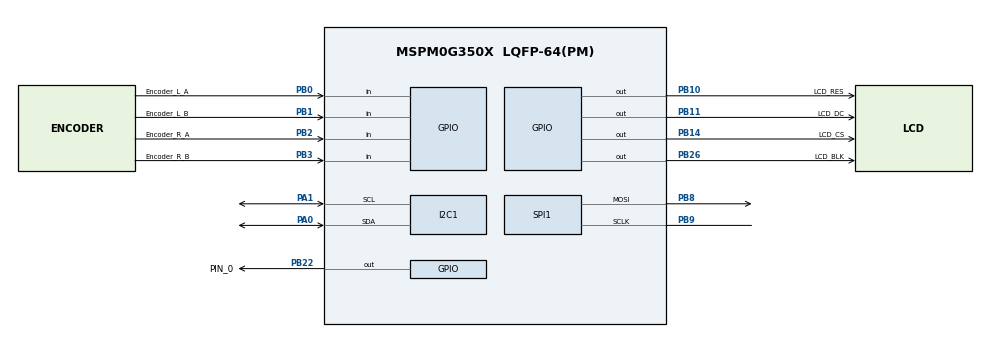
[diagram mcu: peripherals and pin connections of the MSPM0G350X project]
/**
 * @cliArgs --device "MSPM0G350X" --part "Default" --package "LQFP-64(PM)" --product "mspm0_sdk@2.10.00.04"
 * @versions {"tool":"1.26.2+4477"}
 */

/**
 * Import the modules used in this configuration.
 */
const GPIO          = scripting.addModule("/ti/driverlib/GPIO", {}, false);
const GPIO1         = GPIO.addInstance();
const GPIO2         = GPIO.addInstance();
const GPIO3         = GPIO.addInstance();
const I2C           = scripting.addModule("/ti/driverlib/I2C", {}, false);
const I2C1          = I2C.addInstance();
const PWM           = scripting.addModule("/ti/driverlib/PWM", {}, false);
const PWM1          = PWM.addInstance();
const PWM2          = PWM.addInstance();
const SPI           = scripting.addModule("/ti/driverlib/SPI", {}, false);
const SPI1          = SPI.addInstance();
const SYSCTL        = scripting.addModule("/ti/driverlib/SYSCTL");
const SYSTICK       = scripting.addModule("/ti/driverlib/SYSTICK");
const TIMER         = scripting.addModule("/ti/driverlib/TIMER", {}, false);
const TIMER1        = TIMER.addInstance();
const UART          = scripting.addModule("/ti/driverlib/UART", {}, false);
const UART1         = UART.addInstance();
const ProjectConfig = scripting.addModule("/ti/project_config/ProjectConfig");

/**
 * Write custom configuration values to the imported modules.
 */
const divider9       = system.clockTree["UDIV"];
divider9.divideValue = 2;

const mux4       = system.clockTree["EXHFMUX"];
mux4.inputSelect = "EXHFMUX_XTAL";

const mux8       = system.clockTree["HSCLKMUX"];
mux8.inputSelect = "HSCLKMUX_SYSPLL2X";

const mux12       = system.clockTree["SYSPLLMUX"];
mux12.inputSelect = "zSYSPLLMUX_HFCLK";

const pinFunction4       = system.clockTree["HFXT"];
pinFunction4.inputFreq   = 40;
pinFunction4.HFXTStartup = 10;
pinFunction4.enable      = true;

GPIO1.$name                              = "User_led";
GPIO1.associatedPins[0].$name            = "PIN_0";
GPIO1.associatedPins[0].internalResistor = "PULL_DOWN";
GPIO1.associatedPins[0].pin.$assign      = "PB22";

const Board = scripting.addModule("/ti/driverlib/Board", {}, false);

GPIO2.$name                         = "Encoder_Input_Pin";
GPIO2.associatedPins.create(4);
GPIO2.associatedPins[0].$name       = "Encoder_L_A";
GPIO2.associatedPins[0].direction   = "INPUT";
GPIO2.associatedPins[0].interruptEn = true;
GPIO2.associatedPins[0].polarity    = "RISE_FALL";
GPIO2.associatedPins[0].pin.$assign = "PB0";
GPIO2.associatedPins[1].$name       = "Encoder_L_B";
GPIO2.associatedPins[1].direction   = "INPUT";
GPIO2.associatedPins[1].interruptEn = true;
GPIO2.associatedPins[1].polarity    = "RISE_FALL";
GPIO2.associatedPins[1].pin.$assign = "PB1";
GPIO2.associatedPins[2].$name       = "Encoder_R_A";
GPIO2.associatedPins[2].direction   = "INPUT";
GPIO2.associatedPins[2].interruptEn = true;
GPIO2.associatedPins[2].polarity    = "RISE_FALL";
GPIO2.associatedPins[2].pin.$assign = "PB2";
GPIO2.associatedPins[3].$name       = "Encoder_R_B";
GPIO2.associatedPins[3].direction   = "INPUT";
GPIO2.associatedPins[3].interruptEn = true;
GPIO2.associatedPins[3].polarity    = "RISE_FALL";
GPIO2.associatedPins[3].pin.$assign = "PB3";

GPIO3.$name                          = "LCD_CTRL";
GPIO3.associatedPins.create(4);
GPIO3.associatedPins[0].$name        = "LCD_RES";
GPIO3.associatedPins[0].initialValue = "SET";
GPIO3.associatedPins[0].pin.$assign  = "PB10";
GPIO3.associatedPins[1].$name        = "LCD_DC";
GPIO3.associatedPins[1].initialValue = "SET";
GPIO3.associatedPins[1].pin.$assign  = "PB11";
GPIO3.associatedPins[2].$name        = "LCD_CS";
GPIO3.associatedPins[2].initialValue = "SET";
GPIO3.associatedPins[2].pin.$assign  = "PB14";
GPIO3.associatedPins[3].$name        = "LCD_BLK";
GPIO3.associatedPins[3].initialValue = "SET";
GPIO3.associatedPins[3].pin.$assign  = "PB26";

I2C1.$name                           = "I2C_0";
I2C1.basicEnableController           = true;
I2C1.advDigitalGlitchFilter          = "CLOCKS_1";
I2C1.enableDMAEvent1                 = false;
I2C1.enableDMAEvent2                 = false;
I2C1.basicTargetSecAddressEnable     = true;
I2C1.basicEnableTarget               = true;
I2C1.basicControllerStandardBusSpeed = "Fast";
I2C1.peripheral.$assign              = "I2C0";
I2C1.peripheral.sdaPin.$assign       = "PA0";
I2C1.peripheral.sclPin.$assign       = "PA1";
I2C1.sdaPinConfig.$name              = "ti_driverlib_gpio_GPIOPinGeneric0";
I2C1.sclPinConfig.$name              = "ti_driverlib_gpio_GPIOPinGeneric1";

PWM1.timerStartTimer                    = true;
PWM1.clockPrescale                      = 4;
PWM1.$name                              = "motorL";
PWM1.peripheral.$assign                 = "TIMG6";
PWM1.PWM_CHANNEL_0.$name                = "ti_driverlib_pwm_PWMTimerCC0";
PWM1.PWM_CHANNEL_1.$name                = "ti_driverlib_pwm_PWMTimerCC1";
PWM1.ccp0PinConfig.direction            = scripting.forceWrite("OUTPUT");
PWM1.ccp0PinConfig.hideOutputInversion  = scripting.forceWrite(false);
PWM1.ccp0PinConfig.onlyInternalResistor = scripting.forceWrite(false);
PWM1.ccp0PinConfig.passedPeripheralType = scripting.forceWrite("Digital");
PWM1.ccp0PinConfig.$name                = "ti_driverlib_gpio_GPIOPinGeneric4";
PWM1.ccp1PinConfig.direction            = scripting.forceWrite("OUTPUT");
PWM1.ccp1PinConfig.hideOutputInversion  = scripting.forceWrite(false);
PWM1.ccp1PinConfig.onlyInternalResistor = scripting.forceWrite(false);
PWM1.ccp1PinConfig.passedPeripheralType = scripting.forceWrite("Digital");
PWM1.ccp1PinConfig.$name                = "ti_driverlib_gpio_GPIOPinGeneric5";

PWM2.$name                              = "motorR";
PWM2.timerStartTimer                    = true;
PWM2.clockPrescale                      = 4;
PWM2.peripheral.$assign                 = "TIMG7";
PWM2.PWM_CHANNEL_0.$name                = "ti_driverlib_pwm_PWMTimerCC2";
PWM2.PWM_CHANNEL_1.$name                = "ti_driverlib_pwm_PWMTimerCC3";
PWM2.ccp0PinConfig.direction            = scripting.forceWrite("OUTPUT");
PWM2.ccp0PinConfig.hideOutputInversion  = scripting.forceWrite(false);
PWM2.ccp0PinConfig.onlyInternalResistor = scripting.forceWrite(false);
PWM2.ccp0PinConfig.passedPeripheralType = scripting.forceWrite("Digital");
PWM2.ccp0PinConfig.$name                = "ti_driverlib_gpio_GPIOPinGeneric6";
PWM2.ccp1PinConfig.direction            = scripting.forceWrite("OUTPUT");
PWM2.ccp1PinConfig.hideOutputInversion  = scripting.forceWrite(false);
PWM2.ccp1PinConfig.onlyInternalResistor = scripting.forceWrite(false);
PWM2.ccp1PinConfig.passedPeripheralType = scripting.forceWrite("Digital");
PWM2.ccp1PinConfig.$name                = "ti_driverlib_gpio_GPIOPinGeneric7";

SPI1.$name                              = "SPI_LCD";
SPI1.targetBitRate                      = 8000000;
SPI1.frameFormat                        = "MOTO3";
SPI1.direction                          = "PICO";
SPI1.sclkPinConfig.$name                = "ti_driverlib_gpio_GPIOPinGeneric8";
SPI1.sclkPinConfig.direction            = scripting.forceWrite("OUTPUT");
SPI1.sclkPinConfig.onlyInternalResistor = scripting.forceWrite(false);
SPI1.sclkPinConfig.passedPeripheralType = scripting.forceWrite("Digital");
SPI1.peripheral.$assign                 = "SPI1";
SPI1.peripheral.sclkPin.$assign         = "PB9";
SPI1.peripheral.mosiPin.$assign         = "PB8";
SPI1.mosiPinConfig.$name                = "ti_driverlib_gpio_GPIOPinGeneric9";

SYSCTL.clockTreeEn = true;

SYSTICK.periodEnable    = true;
SYSTICK.interruptEnable = true;
SYSTICK.systickEnable   = true;
SYSTICK.period          = 80000;

TIMER1.$name              = "TIMER_0_counter";
TIMER1.timerClkPrescale   = 100;
TIMER1.timerMode          = "PERIODIC";
TIMER1.timerPeriod        = "1ms";
TIMER1.timerStartTimer    = true;
TIMER1.interrupts         = ["ZERO"];
TIMER1.interruptPriority  = "1";
TIMER1.peripheral.$assign = "TIMG0";

UART1.$name                             = "UART_0";
UART1.targetBaudRate                    = 115200;
UART1.enableFIFO                        = true;
UART1.rxFifoThreshold                   = "DL_UART_RX_FIFO_LEVEL_ONE_ENTRY";
UART1.enabledInterrupts                 = ["DMA_DONE_RX","DMA_DONE_TX"];
UART1.enabledDMARXTriggers              = "DL_UART_DMA_INTERRUPT_RX";
UART1.enabledDMATXTriggers              = "DL_UART_DMA_INTERRUPT_TX";
UART1.txPinConfig.$name                 = "ti_driverlib_gpio_GPIOPinGeneric2";
UART1.rxPinConfig.$name                 = "ti_driverlib_gpio_GPIOPinGeneric3";
UART1.DMA_CHANNEL_RX.$name              = "DMA_CH0";
UART1.DMA_CHANNEL_RX.addressMode        = "f2b";
UART1.DMA_CHANNEL_RX.srcLength          = "BYTE";
UART1.DMA_CHANNEL_RX.dstLength          = "BYTE";
UART1.DMA_CHANNEL_RX.transferMode       = "FULL_CH_REPEAT_SINGLE";
UART1.DMA_CHANNEL_RX.peripheral.$assign = "DMA_CH0";
UART1.DMA_CHANNEL_TX.$name              = "DMA_CH1";
UART1.DMA_CHANNEL_TX.enableInterrupt    = true;
UART1.DMA_CHANNEL_TX.srcLength          = "BYTE";
UART1.DMA_CHANNEL_TX.addressMode        = "b2f";
UART1.DMA_CHANNEL_TX.dstLength          = "BYTE";
UART1.DMA_CHANNEL_TX.peripheral.$assign = "DMA_CH1";

ProjectConfig.genLibCMSIS = true;

/**
 * Pinmux solution for unlocked pins/peripherals. This ensures that minor changes to the automatic solver in a future
 * version of the tool will not impact the pinmux you originally saw.  These lines can be completely deleted in order to
 * re-solve from scratch.
 */
pinFunction4.peripheral.$suggestSolution           = "SYSCTL";
pinFunction4.peripheral.hfxInPin.$suggestSolution  = "PA5";
pinFunction4.peripheral.hfxOutPin.$suggestSolution = "PA6";
Board.peripheral.$suggestSolution                  = "DEBUGSS";
Board.peripheral.swclkPin.$suggestSolution         = "PA20";
Board.peripheral.swdioPin.$suggestSolution         = "PA19";
PWM1.peripheral.ccp0Pin.$suggestSolution           = "PA21";
PWM1.peripheral.ccp1Pin.$suggestSolution           = "PA22";
PWM2.peripheral.ccp0Pin.$suggestSolution           = "PA17";
PWM2.peripheral.ccp1Pin.$suggestSolution           = "PA18";
UART1.peripheral.$suggestSolution                  = "UART0";
UART1.peripheral.rxPin.$suggestSolution            = "PA11";
UART1.peripheral.txPin.$suggestSolution            = "PA10";
